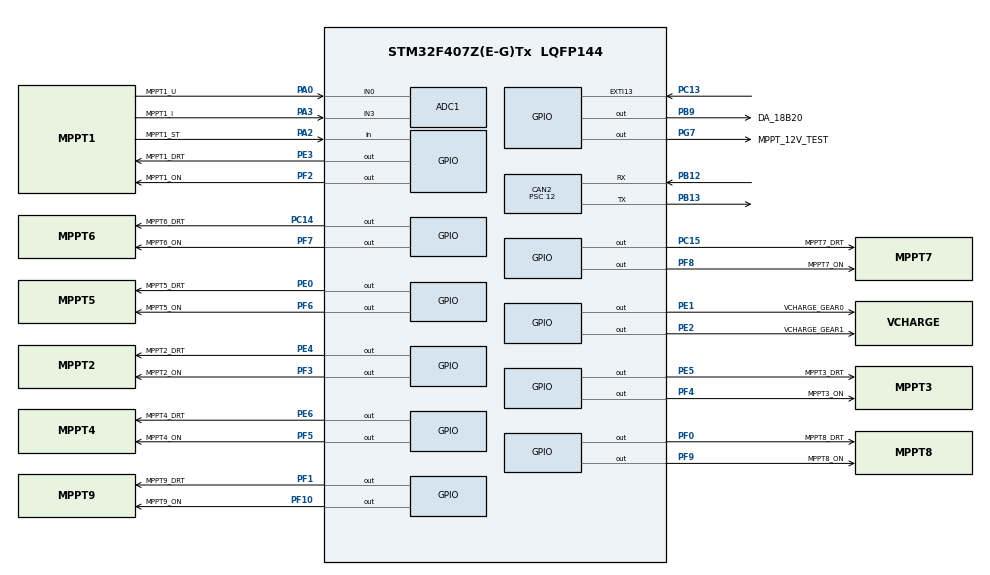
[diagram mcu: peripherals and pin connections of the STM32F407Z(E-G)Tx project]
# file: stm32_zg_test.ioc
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ADC1.Channel-8\#ChannelRegularConversion=ADC_CHANNEL_0
ADC1.Channel-9\#ChannelRegularConversion=ADC_CHANNEL_3
ADC1.ClockPrescaler=ADC_CLOCK_SYNC_PCLK_DIV4
ADC1.ContinuousConvMode=ENABLE
ADC1.DMAContinuousRequests=ENABLE
ADC1.EOCSelection=ADC_EOC_SEQ_CONV
ADC1.InjNumberOfConversion=0
ADC1.NbrOfConversion=2
ADC1.NbrOfConversionFlag=1
ADC1.Rank-8\#ChannelRegularConversion=1
ADC1.Rank-9\#ChannelRegularConversion=2
ADC1.SamplingTime-8\#ChannelRegularConversion=ADC_SAMPLETIME_56CYCLES
ADC1.SamplingTime-9\#ChannelRegularConversion=ADC_SAMPLETIME_56CYCLES
ADC1.ScanConvMode=ENABLE
ADC1.master=1
CAN2.ABOM=ENABLE
CAN2.AWUM=ENABLE
CAN2.BS1=CAN_BS1_4TQ
CAN2.BS2=CAN_BS2_2TQ
CAN2.CalculateBaudRate=500000
CAN2.CalculateTimeBit=2000
CAN2.CalculateTimeQuantum=285.7142857142857
CAN2.Prescaler=12
Dma.ADC1.0.Direction=DMA_PERIPH_TO_MEMORY
Dma.ADC1.0.FIFOMode=DMA_FIFOMODE_DISABLE
Dma.ADC1.0.Instance=DMA2_Stream0
Dma.ADC1.0.MemDataAlignment=DMA_MDATAALIGN_HALFWORD
Dma.ADC1.0.MemInc=DMA_MINC_ENABLE
Dma.ADC1.0.Mode=DMA_CIRCULAR
Dma.ADC1.0.PeriphDataAlignment=DMA_PDATAALIGN_HALFWORD
Dma.ADC1.0.PeriphInc=DMA_PINC_DISABLE
Dma.ADC1.0.Priority=DMA_PRIORITY_LOW
Dma.Request0=ADC1
Mcu.Family=STM32F4
Mcu.Name=STM32F407Z(E-G)Tx
Mcu.Package=LQFP144
NVIC.CAN2_RX1_IRQn=true\:2\:0\:true\:true\:true\:1\:true\:true
NVIC.DMA2_Stream0_IRQn=true\:15\:0\:true\:false\:true\:true\:true
NVIC.EXTI15_10_IRQn=true\:0\:0\:false\:false\:true\:true\:true
NVIC.PriorityGroup=NVIC_PRIORITYGROUP_4
NVIC.TIM6_DAC_IRQn=true\:0\:0\:false\:false\:true\:true\:true
PA0-WKUP.GPIO_Label=MPPT1_U
PA0-WKUP.Signal=ADCx_IN0
PA13.Mode=Serial_Wire
PA13.Signal=SYS_JTMS-SWDIO
PA14.Mode=Serial_Wire
PA14.Signal=SYS_JTCK-SWCLK
PA2.GPIO_Label=MPPT1_ST
PA2.Signal=GPIO_Input
PA3.GPIO_Label=MPPT1_I
PA3.Signal=ADCx_IN3
PB12.Mode=CAN_Activate
PB12.Signal=CAN2_RX
PB13.Mode=CAN_Activate
PB13.Signal=CAN2_TX
PB9.GPIO_Label=DA_18B20
PB9.Signal=GPIO_Output
PC13-ANTI_TAMP.GPIO_ModeDefaultEXTI=GPIO_MODE_IT_FALLING
PC13-ANTI_TAMP.GPIO_PuPd=GPIO_NOPULL
PC13-ANTI_TAMP.Signal=GPXTI13
PC14-OSC32_IN.GPIO_Label=MPPT6_DRT
PC14-OSC32_IN.Signal=GPIO_Output
PC15-OSC32_OUT.GPIO_Label=MPPT7_DRT
PC15-OSC32_OUT.Signal=GPIO_Output
PE0.GPIO_Label=MPPT5_DRT
PE0.Signal=GPIO_Output
PE1.GPIO_Label=VCHARGE_GEAR0
PE1.Signal=GPIO_Output
PE2.GPIO_Label=VCHARGE_GEAR1
PE2.Signal=GPIO_Output
PE3.GPIO_Label=MPPT1_DRT
PE3.Signal=GPIO_Output
PE4.GPIO_Label=MPPT2_DRT
PE4.Signal=GPIO_Output
PE5.GPIO_Label=MPPT3_DRT
PE5.Signal=GPIO_Output
PE6.GPIO_Label=MPPT4_DRT
PE6.Signal=GPIO_Output
PF0.GPIO_Label=MPPT8_DRT
PF0.Signal=GPIO_Output
PF1.GPIO_Label=MPPT9_DRT
PF1.Signal=GPIO_Output
PF10.GPIO_Label=MPPT9_ON
PF10.Signal=GPIO_Output
PF2.GPIO_Label=MPPT1_ON
PF2.GPIO_Speed=GPIO_SPEED_FREQ_VERY_HIGH
PF2.Signal=GPIO_Output
PF3.GPIO_Label=MPPT2_ON
PF3.Signal=GPIO_Output
PF4.GPIO_Label=MPPT3_ON
PF4.Signal=GPIO_Output
PF5.GPIO_Label=MPPT4_ON
PF5.Signal=GPIO_Output
PF6.GPIO_Label=MPPT5_ON
PF6.Signal=GPIO_Output
PF7.GPIO_Label=MPPT6_ON
PF7.Signal=GPIO_Output
PF8.GPIO_Label=MPPT7_ON
PF8.Signal=GPIO_Output
PF9.GPIO_Label=MPPT8_ON
PF9.Signal=GPIO_Output
PG7.GPIO_Label=MPPT_12V_TEST
PG7.PinState=GPIO_PIN_RESET
PG7.Signal=GPIO_Output
PH0-OSC_IN.Mode=HSE-External-Oscillator
PH0-OSC_IN.Signal=RCC_OSC_IN
PH1-OSC_OUT.Mode=HSE-External-Oscillator
PH1-OSC_OUT.Signal=RCC_OSC_OUT
ProjectManager.HeapSize=0x200
ProjectManager.StackSize=0x400
ProjectManager.TargetToolchain=MDK-ARM V5.32
RCC.48MHZClocksFreq_Value=24000000
RCC.AHBFreq_Value=84000000
RCC.APB1CLKDivider=RCC_HCLK_DIV2
RCC.APB1Freq_Value=42000000
RCC.APB1TimFreq_Value=84000000
RCC.APB2CLKDivider=RCC_HCLK_DIV2
RCC.APB2Freq_Value=42000000
RCC.APB2TimFreq_Value=84000000
RCC.CortexFreq_Value=84000000
RCC.HCLKFreq_Value=84000000
RCC.HSE_VALUE=25000000
RCC.HSI_VALUE=16000000
RCC.LSE_VALUE=32768
RCC.PLLM=25
RCC.PLLN=168
RCC.PLLQ=7
RCC.PLLSourceVirtual=RCC_PLLSOURCE_HSE
RCC.SYSCLKFreq_VALUE=84000000
RCC.SYSCLKSource=RCC_SYSCLKSOURCE_PLLCLK
RCC.VCOOutputFreq_Value=168000000
SH.ADCx_IN0.0=ADC1_IN0,IN0
SH.ADCx_IN3.0=ADC1_IN3,IN3
TIM6.Period=8399
TIM7.Prescaler=83
VP_TIM6_VS_ClockSourceINT.Mode=Enable_Timer
VP_TIM7_VS_ClockSourceINT.Mode=Enable_Timer
board=custom

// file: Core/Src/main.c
/* USER CODE BEGIN Header */
/**
  ******************************************************************************
  * @file           : main.c
  * @brief          : Main program body
  ******************************************************************************
  * @attention
  *
  * Copyright (c) 2024 STMicroelectronics.
  * All rights reserved.
  *
  * This software is licensed under terms that can be found in the LICENSE file
  * in the root directory of this software component.
  * If no LICENSE file comes with this software, it is provided AS-IS.
  *
  ******************************************************************************
  */
/* USER CODE END Header */
#include "main.h"
#include "adc.h"
#include "can.h"
#include "dma.h"
#include "tim.h"
#include "gpio.h"

/* USER CODE BEGIN Includes */
#include "can_app.h"
#include "temperature.h"
/* USER CODE END Includes */

void SystemClock_Config(void);
static void MX_NVIC_Init(void);

/* USER CODE BEGIN 0 */
uint8_t running = 0;
/* USER CODE END 0 */

int main(void)
{

  /* MCU Configuration--------------------------------------------------------*/

  /* Reset of all peripherals, Initializes the Flash interface and the Systick. */
  HAL_Init();

  /* Configure the system clock */
  SystemClock_Config();

  /* Initialize all configured peripherals */
  MX_GPIO_Init();
  MX_CAN2_Init();
  MX_DMA_Init();
  MX_ADC1_Init();
  MX_TIM7_Init();
  MX_TIM6_Init();

  /* Initialize interrupts */
  MX_NVIC_Init();
  /* USER CODE BEGIN 2 */

	SysTick_Config(SystemCoreClock / (1000000/SYSTICK_HANDLE_US));//SysTick_Handler 10us
  DS18B20_Init();
  /* USER CODE END 2 */

  /* Infinite loop */
  /* USER CODE BEGIN WHILE */
  while (1)
  {

		//LL_mDelay(500);
    /* USER CODE END WHILE */

    /* USER CODE BEGIN 3 */
    //LL_mDelay(500);
	dh_gpio_main_process();
	dh_can_data_send_process();
		dh_ds18b20_process();
		running++;
	//dh_timer_us_block_delay(5);
	//HAL_GPIO_TogglePin(MPPT1_ON_GPIO_Port, MPPT1_ON_Pin);
  }
  /* USER CODE END 3 */
}

void SystemClock_Config(void)
{
  LL_FLASH_SetLatency(LL_FLASH_LATENCY_2);
  while(LL_FLASH_GetLatency()!= LL_FLASH_LATENCY_2)
  {
  }
  LL_PWR_SetRegulVoltageScaling(LL_PWR_REGU_VOLTAGE_SCALE1);
  LL_RCC_HSE_Enable();

   /* Wait till HSE is ready */
  while(LL_RCC_HSE_IsReady() != 1)
  {

  }
  LL_RCC_PLL_ConfigDomain_SYS(LL_RCC_PLLSOURCE_HSE, LL_RCC_PLLM_DIV_25, 168, LL_RCC_PLLP_DIV_2);
  LL_RCC_PLL_Enable();

   /* Wait till PLL is ready */
  while(LL_RCC_PLL_IsReady() != 1)
  {

  }
  LL_RCC_SetAHBPrescaler(LL_RCC_SYSCLK_DIV_1);
  LL_RCC_SetAPB1Prescaler(LL_RCC_APB1_DIV_2);
  LL_RCC_SetAPB2Prescaler(LL_RCC_APB2_DIV_2);
  LL_RCC_SetSysClkSource(LL_RCC_SYS_CLKSOURCE_PLL);

   /* Wait till System clock is ready */
  while(LL_RCC_GetSysClkSource() != LL_RCC_SYS_CLKSOURCE_STATUS_PLL)
  {

  }
  LL_SetSystemCoreClock(84000000);

   /* Update the time base */
  if (HAL_InitTick (TICK_INT_PRIORITY) != HAL_OK)
  {
    Error_Handler();
  }
}

/**
  * @brief NVIC Configuration.
  * @retval None
  */
static void MX_NVIC_Init(void)
{
  /* CAN2_RX1_IRQn interrupt configuration */
  HAL_NVIC_SetPriority(CAN2_RX1_IRQn, 2, 0);
  HAL_NVIC_EnableIRQ(CAN2_RX1_IRQn);
}

void Error_Handler(void)
{
  __disable_irq();
  while (1)
  {
  }
}
